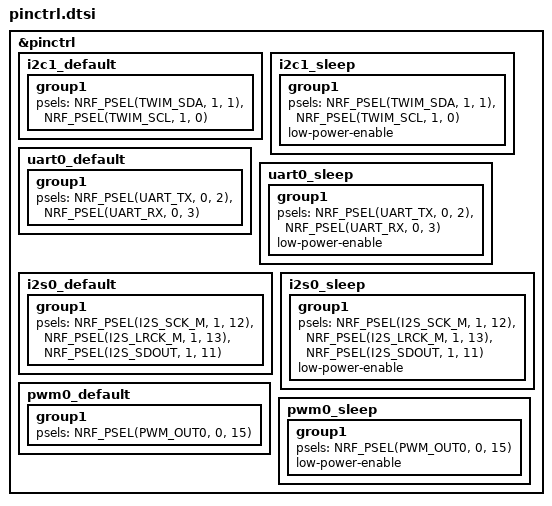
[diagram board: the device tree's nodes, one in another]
&pinctrl {
	i2c1_default: i2c1_default {
		group1 {
			psels = <NRF_PSEL(TWIM_SDA, 1, 1)>, <NRF_PSEL(TWIM_SCL, 1, 0)>;
		};
	};

	i2c1_sleep: i2c1_sleep {
		group1 {
			psels = <NRF_PSEL(TWIM_SDA, 1, 1)>, <NRF_PSEL(TWIM_SCL, 1, 0)>;
			low-power-enable;
		};
	};

	uart0_default: uart0_default {
		group1 {
			psels = <NRF_PSEL(UART_TX, 0, 2)>, <NRF_PSEL(UART_RX, 0, 3)>;
		};
	};

	uart0_sleep: uart0_sleep {
		group1 {
			psels = <NRF_PSEL(UART_TX, 0, 2)>, <NRF_PSEL(UART_RX, 0, 3)>;
			low-power-enable;
		};
	};

	i2s0_default: i2s0_default {
		group1 {
			psels = <NRF_PSEL(I2S_SCK_M, 1, 12)>, <NRF_PSEL(I2S_LRCK_M, 1, 13)>,
				<NRF_PSEL(I2S_SDOUT, 1, 11)>;
		};
	};

	i2s0_sleep: i2s0_sleep {
		group1 {
			psels = <NRF_PSEL(I2S_SCK_M, 1, 12)>, <NRF_PSEL(I2S_LRCK_M, 1, 13)>,
				<NRF_PSEL(I2S_SDOUT, 1, 11)>;
			low-power-enable;
		};
	};

	pwm0_default: pwm0_default {
		group1 {
			psels = <NRF_PSEL(PWM_OUT0, 0, 15)>;
		};
	};

	pwm0_sleep: pwm0_sleep {
		group1 {
			psels = <NRF_PSEL(PWM_OUT0, 0, 15)>;
			low-power-enable;
		};
	};
};
